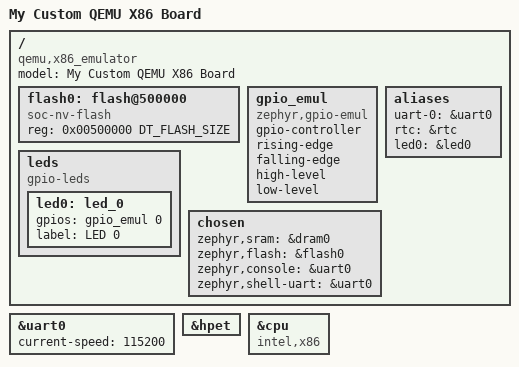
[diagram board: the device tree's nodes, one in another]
/* SPDX-License-Identifier: Apache-2.0 */

/dts-v1/;

#include <mem.h>

#ifndef DT_DRAM_BASE
#define DT_DRAM_BASE		0
#endif
#ifndef DT_DRAM_SIZE
#define DT_DRAM_SIZE		DT_SIZE_M(32)
#endif
#define DT_FLASH_SIZE		DT_SIZE_K(4096)

#include <intel/atom.dtsi>
#include <zephyr/dt-bindings/gpio/gpio.h>

/ {
	model = "My Custom QEMU X86 Board";
	compatible = "qemu,x86_emulator";

	flash0: flash@500000 {
		compatible = "soc-nv-flash";
		reg = <0x00500000 DT_FLASH_SIZE>;
	};

	gpio_emul: gpio_emul {
		compatible = "zephyr,gpio-emul";
		gpio-controller;
		#gpio-cells = <2>;
		rising-edge;
		falling-edge;
		high-level;
		low-level;
	};

	aliases {
		uart-0 = &uart0;
		rtc = &rtc;
		led0 = &led0;
	};

	leds {
		compatible = "gpio-leds";
		led0: led_0 {
			gpios = <&gpio_emul 0 GPIO_ACTIVE_HIGH>;
			label = "LED 0";
		};
	};

	chosen {
		zephyr,sram = &dram0;
		zephyr,flash = &flash0;
		zephyr,console = &uart0;
		zephyr,shell-uart = &uart0;
	};
};

&uart0 {
	status = "okay";
	current-speed = <115200>;
};

&hpet {
	status = "okay";
};

&cpu {
	compatible = "intel,x86";
};
